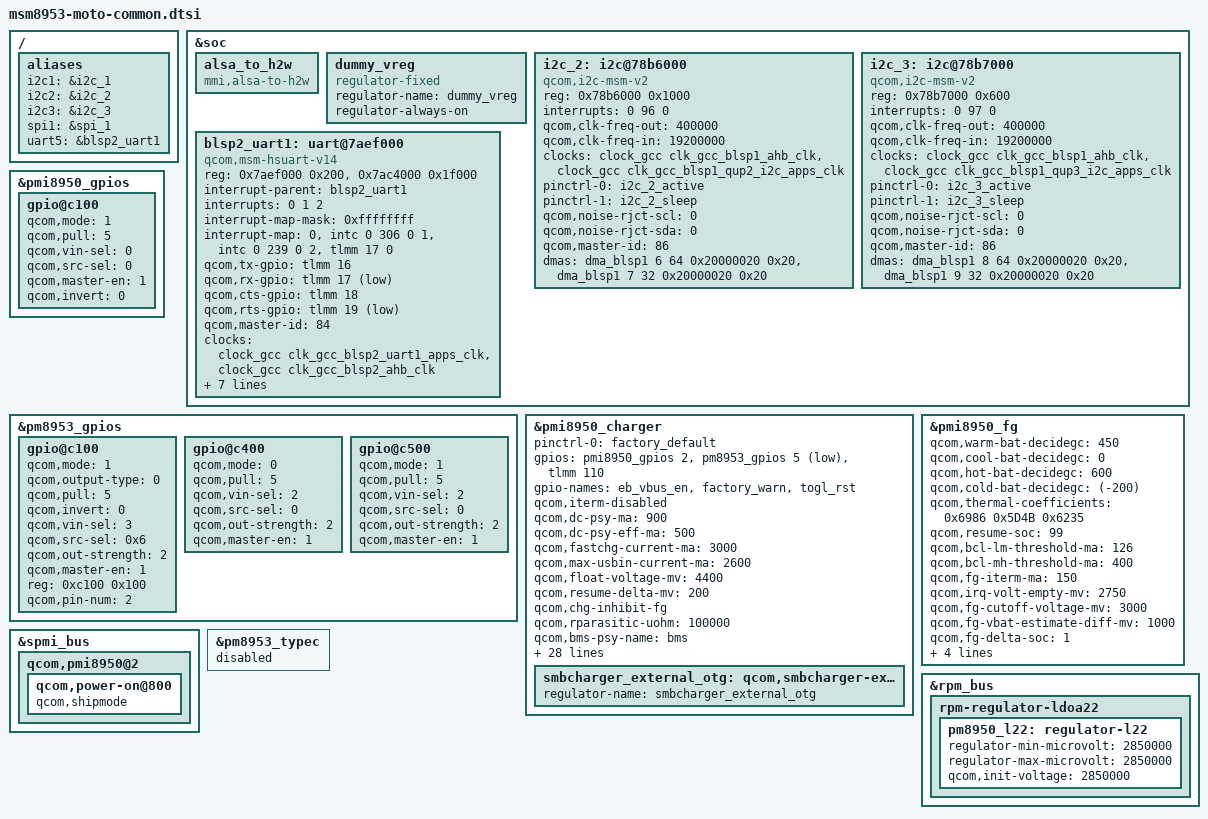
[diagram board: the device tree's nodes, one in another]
/* Copyright (c) 2016, Motorola Mobility Inc. All rights reserved.
 *
 * This program is free software; you can redistribute it and/or modify
 * it under the terms of the GNU General Public License version 2 and
 * only version 2 as published by the Free Software Foundation.
 *
 * This program is distributed in the hope that it will be useful,
 * but WITHOUT ANY WARRANTY; without even the implied warranty of
 * MERCHANTABILITY or FITNESS FOR A PARTICULAR PURPOSE.  See the
 * GNU General Public License for more details.
 */

/ {
	aliases {
		i2c1 = &i2c_1;
		i2c2 = &i2c_2;
		i2c3 = &i2c_3;
		spi1 = &spi_1;
		uart5 = &blsp2_uart1;
		/delete-property/ spi3;
		/delete-property/ i2c5;
	};
};

&soc{
	/delete-node/ uart@78b0000;
	/delete-node/ uart@7aef000;
	/delete-node/ i2c@7af5000;
	/delete-node/ spi@78b7000;
	/delete-node/ adv_vreg;
	/delete-node/ sound-9335;

	alsa_to_h2w {
		compatible = "mmi,alsa-to-h2w";
	};

	dummy_vreg: dummy_vreg {
		compatible = "regulator-fixed";
		status = "ok";
		regulator-name = "dummy_vreg";
		regulator-always-on;
	};

	i2c_2: i2c@78b6000 { /* BLSP1 QUP2 */
		compatible = "qcom,i2c-msm-v2";
		#address-cells = <1>;
		#size-cells = <0>;
		reg-names = "qup_phys_addr";
		reg = <0x78b6000 0x1000>;
		interrupt-names = "qup_irq";
		interrupts = <0 96 0>;
		qcom,clk-freq-out = <400000>;
		qcom,clk-freq-in  = <19200000>;
		clock-names = "iface_clk", "core_clk";
		clocks = <&clock_gcc clk_gcc_blsp1_ahb_clk>,
			<&clock_gcc clk_gcc_blsp1_qup2_i2c_apps_clk>;

		pinctrl-names = "i2c_active", "i2c_sleep";
		pinctrl-0 = <&i2c_2_active>;
		pinctrl-1 = <&i2c_2_sleep>;
		qcom,noise-rjct-scl = <0>;
		qcom,noise-rjct-sda = <0>;
		qcom,master-id = <86>;
		dmas = <&dma_blsp1 6 64 0x20000020 0x20>,
			<&dma_blsp1 7 32 0x20000020 0x20>;
		dma-names = "tx", "rx";

		/delete-node/ adv7533@39;

	};

	i2c_3: i2c@78b7000 { /* BLSP1 QUP3 */
		status = "okay";
		compatible = "qcom,i2c-msm-v2";
		#address-cells = <1>;
		#size-cells = <0>;
		reg-names = "qup_phys_addr";
		reg = <0x78b7000 0x600>;
		interrupt-names = "qup_irq";
		interrupts = <0 97 0>;
		qcom,clk-freq-out = <400000>;
		qcom,clk-freq-in  = <19200000>;
		clock-names = "iface_clk", "core_clk";
		clocks = <&clock_gcc clk_gcc_blsp1_ahb_clk>,
			<&clock_gcc clk_gcc_blsp1_qup3_i2c_apps_clk>;

		pinctrl-names = "i2c_active", "i2c_sleep";
		pinctrl-0 = <&i2c_3_active>;
		pinctrl-1 = <&i2c_3_sleep>;
		qcom,noise-rjct-scl = <0>;
		qcom,noise-rjct-sda = <0>;
		qcom,master-id = <86>;
		dmas = <&dma_blsp1 8 64 0x20000020 0x20>,
			<&dma_blsp1 9 32 0x20000020 0x20>;
		dma-names = "tx", "rx";
	};

	blsp2_uart1: uart@7aef000 { /* BLSP2 UART1 */
		compatible = "qcom,msm-hsuart-v14";
		reg = <0x7aef000 0x200>,
			<0x7ac4000 0x1f000>;
		reg-names = "core_mem", "bam_mem";

		interrupt-names = "core_irq", "bam_irq", "wakeup_irq";
		#address-cells = <0>;
		interrupt-parent = <&blsp2_uart1>;
		interrupts = <0 1 2>;
		#interrupt-cells = <1>;
		interrupt-map-mask = <0xffffffff>;
		interrupt-map = <0 &intc 0 306 0
				1 &intc 0 239 0
				2 &tlmm 17 0>;

		qcom,tx-gpio = <&tlmm 16 0>;
		qcom,rx-gpio = <&tlmm 17 1>;
		qcom,cts-gpio = <&tlmm 18 0>;
		qcom,rts-gpio = <&tlmm 19 1>;
		qcom,master-id = <84>;
		clock-names = "core_clk", "iface_clk";
		clocks = <&clock_gcc clk_gcc_blsp2_uart1_apps_clk>,
			<&clock_gcc clk_gcc_blsp2_ahb_clk>;
		qcom,bam-tx-ep-pipe-index = <0>;
		qcom,bam-rx-ep-pipe-index = <1>;
		qcom,msm-bus,name = "blsp2_uart1";
		qcom,msm-bus,num-cases = <2>;
		qcom,msm-bus,num-paths = <1>;
		qcom,msm-bus,vectors-KBps =
				<84 512 0 0>,
				<84 512 500 800>;
		status = "ok";
	};
};

&pmi8950_gpios {
	gpio@c100 {
		qcom,mode = <1>;	/* Digital output */
		qcom,pull = <5>;	/* No Pull */
		qcom,vin-sel = <0>;	/* 1.8 */
		qcom,src-sel = <0>;	/* GPIO */
		qcom,master-en = <1>;	/* Enable GPIO */
		qcom,invert = <0>;	/* Output Low */
		status = "okay";
	};
};

&pm8953_gpios {
	gpio@c100 {
		status = "okay";
		qcom,mode = <1>; /* Digital output */
		qcom,output-type = <0>; /* CMOS logic */
		qcom,pull = <5>; /* From QC */
		qcom,invert = <0>; /* Output low initially */
		qcom,vin-sel = <3>; /* VIN 3 */
		qcom,src-sel = <0x6>; /* DTEST3 */
		qcom,out-strength = <2>; /* Medium */
		qcom,master-en = <1>; /* Enable GPIO */
		reg = <0xc100 0x100>;
		qcom,pin-num = <2>;
	};

	gpio@c400 {
		qcom,mode = <0>;		/* Digital Input */
		qcom,pull = <5>;		/* No pull  */
		qcom,vin-sel = <2>;		/* VIN0 */
		qcom,src-sel = <0>;		/* GPIO */
		qcom,out-strength = <2>;        /* Medium */
		qcom,master-en = <1>;		/* Enable GPIO */
		status = "okay";
	};

	gpio@c500 { /* GPIO 6 - USB_SELECT */
		qcom,mode = <1>;		/* Digital Output */
		qcom,pull = <5>;		/* No pull  */
		qcom,vin-sel = <2>;		/* VIN0 */
		qcom,src-sel = <0>;		/* GPIO */
		qcom,out-strength = <2>;        /* Medium */
		qcom,master-en = <1>;		/* Enable GPIO */
		status = "okay";
	};
};

&pmi8950_charger {
	status = "okay";
	pinctrl-names = "default";
	pinctrl-0 = <&factory_default>;
	gpios = <&pmi8950_gpios 2 0x0>, /* GPIOF_OUT_INIT_LOW */
		<&pm8953_gpios 5 0x1>, /* GPIOF_IN */
		<&tlmm 110 0x0>; /* GPIOF_OUT_INIT_LOW */
	gpio-names = "eb_vbus_en",
		     "factory_warn",
		     "togl_rst";
	/delete-property/ qcom,iterm-ma;
	qcom,iterm-disabled;
	/delete-property/ qcom,autoadjust-vfloat;
	/delete-property/ qcom,dc-psy-type;
	qcom,dc-psy-ma = <900>;
	qcom,dc-psy-eff-ma = <500>;
	qcom,fastchg-current-ma = <3000>;
	qcom,max-usbin-current-ma = <2600>;
	qcom,float-voltage-mv = <4400>;
	qcom,resume-delta-mv = <200>;
	qcom,chg-inhibit-fg;
	qcom,rparasitic-uohm = <100000>;
	qcom,bms-psy-name = "bms";
	qcom,eb-batt-psy-name = "gb_battery";
	qcom,eb-pwr-psy-name = "gb_ptp";
	qcom,charge-unknown-battery;
	qcom,chg-thermal-mitigation = <3000 0>,
				      <2500 0>,
				      <2000 0>,
				      <1500 0>,
				      <1000 0>,
				      <500 0>;
	qcom,dc-thermal-mitigation = <2000>,
				     <1500>,
				     <900>,
				     <600>,
				     <300>;
	qcom,thermal-mitigation = <3000 0>,
				  <2500 0>,
				  <2000 0>,
				  <1500 0>,
				  <1000 0>,
				  <500 0>,
				  <300 0>;
	qcom,step-chg-steps = <4200 3000 2400>,
				<4400 2400 2000>;
	qcom,stepchg-iterm-ma = <170>;
	qcom,hot-temp-c = <60>;
	qcom,cold-temp-c = <(-20)>;
	qcom,warm-temp-c = <45>;
	qcom,cool-temp-c = <0>;
	qcom,ext-temp-volt-mv = <4200>;
	qcom,hotspot-thrs-c = <50>;
	qcom,charging-timeout-mins = <0>;
	qcom,precharging-timeout-mins = <0>;
	qcom,bmd-algo-disabled;
	qcom,bmd-pin-src = "bpd_none";
	qcom,usbid-disabled;
	qcom,force-aicl-rerun;
	mmi,fake-factory-type;
	qcom,auto-voltage-comp-mv = <75>;
	qcom,usbin-vadc = <&pmi8950_vadc>;
	qcom,dcin-vadc = <&pmi8950_vadc>;

	smbcharger_external_otg: qcom,smbcharger-external-otg {
		status = "okay";
		regulator-name = "smbcharger_external_otg";
	};
};

&pmi8950_fg {
	status = "okay";
	qcom,warm-bat-decidegc = <450>;
	qcom,cool-bat-decidegc = <0>;
	qcom,hot-bat-decidegc = <600>;
	qcom,cold-bat-decidegc = <(-200)>;
	qcom,thermal-coefficients =  /bits/ 16 <0x6986 0x5D4B 0x6235>;
	qcom,resume-soc = <99>;
	qcom,bcl-lm-threshold-ma = <126>;
	qcom,bcl-mh-threshold-ma = <400>;
	qcom,fg-iterm-ma = <150>;
	qcom,irq-volt-empty-mv = <2750>;
	qcom,fg-cutoff-voltage-mv = <3000>;
	qcom,fg-vbat-estimate-diff-mv = <1000>;
	qcom,fg-delta-soc = <1>;
	qcom,fg-max-soc = <100>;
	qcom,fg-min-soc = <0>;
	qcom,fg-cc-cv-threshold-mv = <4390>;
	/delete-property/ qcom,capacity-learning-feedback;
	qcom,battery-data = <&mot_batterydata>;
};

&spmi_bus {
	qcom,pmi8950@2 {
		qcom,power-on@800 {
			qcom,shipmode;
		};
	};
};

&pm8953_typec {
	status = "disabled";
};

&rpm_bus {
	rpm-regulator-ldoa22 {
	pm8950_l22: regulator-l22 {
			regulator-min-microvolt = <2850000>;
			regulator-max-microvolt = <2850000>;
			qcom,init-voltage = <2850000>;
		};
	};
};
